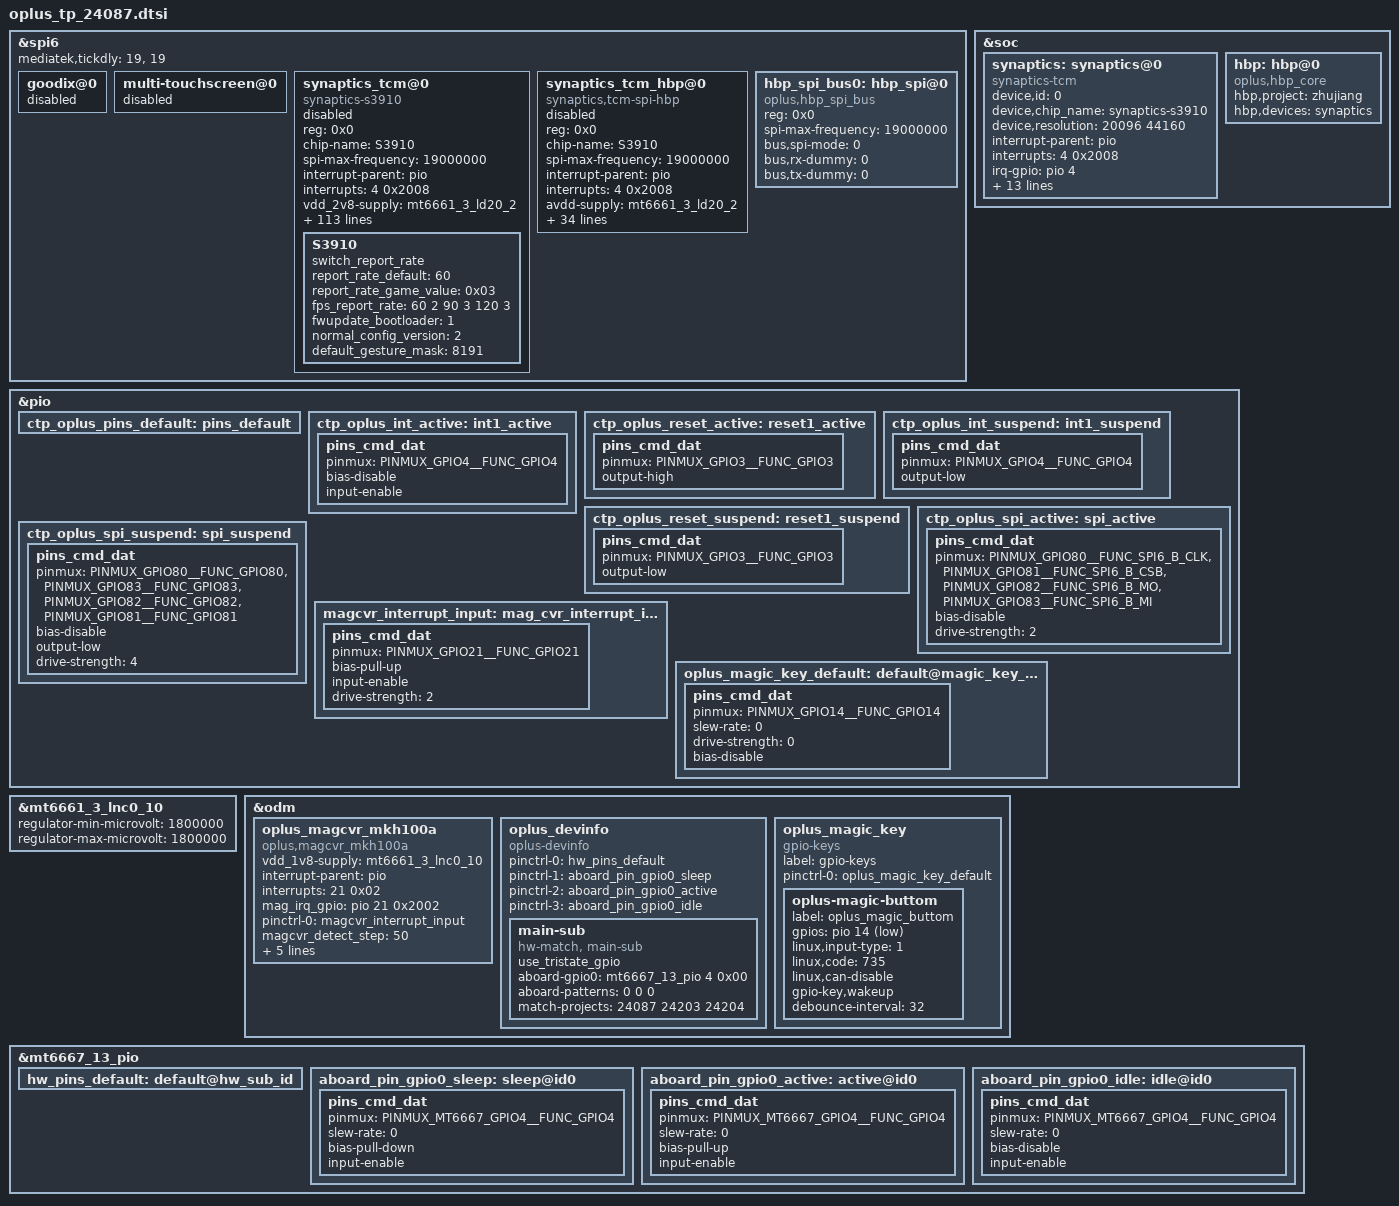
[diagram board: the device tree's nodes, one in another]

#include <dt-bindings/pinctrl/mt6667-pinfunc.h>

/* TOUCH start */

&spi6 {
	status = "okay";
	#address-cells = <1>;
	#size-cells = <0>;
	mediatek,tickdly = <19>, <19>;

	goodix@0{
		status = "disabled";
	};

	multi-touchscreen@0{
		status = "disabled";
	};

	synaptics_tcm@0{
		compatible = "synaptics-s3910";
		reg = <0x0>;
		chip-name = "S3910";
		status = "disabled";
		spi-max-frequency = <19000000>;
		/* Interrupt && Irq-gpio */
		interrupt-parent = <&pio>;
		interrupts = <4 0x2008>;

		/* Power Config */
		/* enable2v8_gpio  = <&pio 164 0x1>; */
		vdd_2v8-supply = <&mt6661_3_ld20_2>;
		vdd_2v8_volt = <3000000>;
		vcc_1v8-supply  = <&mt6661_5_ln60_7>;
		vcc_1v8_volt = <1800000>;

		/* Other HW Resource */

		irq-gpio = <&pio 4 0x2008>;
		reset-gpio = <&pio 3 0x1>;
		//cs-gpio = <&pio 110 0x00>;

		pinctrl-names = "default",  "oplus_int_active",
		"oplus_reset_active", "oplus_int_suspend",
		"oplus_reset_suspend", "oplus_spi_active",
		"oplus_spi_suspend";
		pinctrl-0 = <&ctp_oplus_pins_default>;
		pinctrl-1 = <&ctp_oplus_int_active>;
		pinctrl-2 = <&ctp_oplus_reset_active>;
		pinctrl-3 = <&ctp_oplus_int_suspend>;
		pinctrl-4 = <&ctp_oplus_reset_suspend>;
		pinctrl-5 = <&ctp_oplus_spi_active>;
		pinctrl-6 = <&ctp_oplus_spi_suspend>;

		touchpanel,max-num-support = <10>;
		touchpanel,tx-rx-num = <18 40>;
		touchpanel,panel-coords = <12560 27600>;
		touchpanel,display-coords = <1256 2760>;
		touchpanel,touchmajor-limit = <128 216>;
		touchpanel,elimination-range = <20 200 200>;
		touchpanel,int-mode = <1>; /*0: interrupt and disable, 1:interrupt and not disable*/
		touchpanel,smooth-level = <0 1 2 4 7 9>;
		touchpanel,smooth-level-charging = <0 2 4 7 8 9>;
		touchpanel,sensitive-level = <0 70 55 40 25 10>;
		touchpanel,single-optimized-time = <8>;
		touchpanel,high-frame-rate-time = <60>;

		vid_len = <2>;
		panel_type = <7>; /*type:3 BOE, 7 TM*/
		platform_support_project = <24087 24203 24204>;
		platform_support_project_dir = <24087 24087 24087>;
		platform_support_project_commandline = "panel_ac287_p_7_a0020_dsi_cmd";

		prevention,curved_screen_V2;
		prevention,grip_disable_level = <6>;
		prevention,updelay_time_ms = <30>;
		prevention,makeup_cnt_weight = <4 1 2 2 2>;
		prevention,large_corner_range = <1380 3400>;
		prevention,large_corner_judge_condition = <500 300 1000 7 7>;
		prevention,trx_reject_condition = <8 7 7>;
		prevention,trx_strict_reject_condition = <8 6 6>;
		prevention,large_judge_time_ms = <500 50 30>;
		prevention,large_exit_condition = <8 8 2>;
		prevention,single_channel_width = <320 320>;
		prevention,normal_tap_condition = <10 350>;
		prevention,long_edge_condition = <179 90 120 80>;
		prevention,long_strict_edge_condition = <160 60>;
		prevention,long_fingerhold_condition = <70 6 4 4>;
		prevention,short_edge_condition = <179 90 120 80>;
		prevention,short_strict_edge_condition = <160 60>;
		prevention,large_strict_exit_condition = <6 6>;
		prevention,top_corner_config = <250 750 1000>;
		prevention,edge_swipe_config = <340 1130>;

		prevention,curved_screen_V4;
		prevention,long_eliminate_point_type = <2 12400 9240 240 27720 300 1>;
		prevention,long_fingerhold_condition2 = <700 2000 0 0>;
		prevention,top_corner_config2 =<3 80 600 1500 0>;
		prevention,hor_long_top_corner_config =<300 2000 0 0>;
		prevention,top_middle_config =<12400 1000 1000 0>;
		prevention,corner_eliminate_point_type =<0 1380 2270 1>;
		prevention,finger_hold_differ_size = <1 0 400 300>;
		prevention,finger_hold_max_rx_exit_distance = <5 350 2300>;
		prevention,max_rx_exit_distance = <1 5 150 350 2000>;
		prevention,dynamic_finger_hold_exit_distance = <1 350 2300 450>;
		prevention,edge_sliding_matched_support = <1 150 3 0>;

		//grip v4.2 reclining mode
		prevention,reclining_mode_support = <1>;
		prevention,long_eliminate_point_type_recli = <2 12400 9240 240 27720 500 1>;
		prevention,finger_hold_differ_size_recli = <1 0 400 400>;
		prevention,finger_hold_max_rx_exit_distance_recli = <5 350 2300>;
		prevention,max_rx_exit_distance_recli = <1 5 100 350 2300>;
		prevention,dynamic_finger_hold_exit_distance_recli = <1 350 2300 450>;
		prevention,edge_sliding_matched_support_recli = <1 150 3 0>;
		prevention,long_edge_condition_recli = <179 90 120 80>;

		/* SW Support Feature Control */
		black_gesture_support;
		sportify_aod_gesture_support;
		pressure_report_support;
		charger_pump_support;
		game_switch_support;
		glove_mode_support;
		smart_gesture_support;
		fw_update_app_support;
		fingerprint_underscreen_support;
		freq_hop_simulate_support;
		report_flow_unlock_support;
		screenoff_fingerprint_info_support;
		irq_need_dev_resume_ok;
		enable_point_auto_change;
		kernel_grip_support;
		//grip_no_driver_support;
		health_monitor_support;
		black_gesture_indep_support;
		snr_read_support;
		palm_to_sleep_support;
		exception_upload_support;
		tp_data_record_support;
		fingerprint_not_report_in_suspend;
		/*
		 *Virtual Key Config:
		 *1:touchpanel,button-type: <virtualkey_type  supportted_button-map>
		 *virtualkey_type:
		 *Type 1: using board_properties
		 *Type 2: using same IC (button zone&& touch zone are seprate)
		 *Type 3: using diffrent IC (button zone&& touch zone are seprate)
		 *Type 4: No need of virtual key process
		 *supportted_button-map:select|menu|home|back
		 *
		 *2:touchpanel,button-map
		 *type (X1,Y1)(X2,Y2)(X3,Y3)(Width_X,Hight_Y)--Only when button-type is 0
		 */
		touchpanel,button-type = <4>;
		touchpanel.button-TRx = <0 0>;

		S3910 {
			switch_report_rate;
			report_rate_default = <60>;
			report_rate_game_value = <0x03>;
			fps_report_rate = <60 2 90 3 120 3>;//1:360Hz 2:125Hz 3:240Hz
			fwupdate_bootloader = <1>;
			normal_config_version = <2>;
			default_gesture_mask = <8191>;
		};
	};
	synaptics_tcm_hbp@0{
		compatible = "synaptics,tcm-spi-hbp";
		reg = <0x0>;
		chip-name = "S3910";
		status = "disabled";
		spi-max-frequency = <19000000>;

		/* Interrupt && Irq-gpio */
		interrupt-parent = <&pio>;
		interrupts = <4 0x2008>;

		/* Power Config */
		/* enable2v8_gpio  = <&pio 164 0x1>; */
		/* synaptics,avdd-gpio = <&pio 186 0x1>; */
		avdd-supply = <&mt6661_3_ld20_2>;
		synaptics,avdd-name = "avdd";
		synaptics,vdd_2v8_volt = <3000000>;
		vdd-supply  = <&mt6661_5_ln60_7>;
		synaptics,vdd-name = "vdd";

		/* Other HW Resource */

		synaptics,irq-gpio = <&pio 4 0x2008>;
		synaptics,reset-gpio = <&pio 3 0x1>;
		//cs-gpio = <&pio 110 0x00>;

		pinctrl-names = "default", "ts_spi_active", "ts_spi_suspend";
		pinctrl-0 = <&ctp_oplus_pins_default>;
		pinctrl-1 = <&ctp_oplus_int_active &ctp_oplus_reset_active &ctp_oplus_spi_active>;
		pinctrl-2 = <&ctp_oplus_int_suspend &ctp_oplus_reset_suspend &ctp_oplus_spi_suspend>;

		touchpanel,max-num-support = <10>;
		touchpanel,tx-rx-num = <18 40>;
		touchpanel,panel-coords = <20096 44160>;
		touchpanel,display-coords = <1256 2760>;
		vid_len = <2>;
		panel_type = <7>; /*type:3 BOE, 7 TM*/
		platform_support_project = <24087 24203 24204>;
		platform_support_project_dir = <24087 24087 24087>;
		platform_support_project_commandline = "panel_ac287_p_7_a0020_dsi_cmd";

		synaptics,power-on-state = <1>;
		synaptics,power-delay-ms = <200>;
		synaptics,irq-on-state = <0>;
		synaptics,reset-on-state = <0>;
		synaptics,reset-active-ms = <10>;
		synaptics,reset-delay-ms = <80>;
		synaptics,spi-mode = <0>;
		synaptics,spi-byte-delay-us = <0>;
		synaptics,spi-block-delay-us = <0>;

		tp_data_record_support;
		stats_upload_support;
	};

	hbp_spi_bus0:hbp_spi@0 {
		compatible = "oplus,hbp_spi_bus";
		reg = <0x0>;
		status = "okay";

		spi-max-frequency = <19000000>;
		bus,spi-mode = <0>;
		bus,rx-dummy = <0>;
		bus,tx-dummy = <0>;
	};
};

&soc {
	synaptics:synaptics@0 {
		compatible = "synaptics-tcm";
		status = "okay";

		device,id = <0>;
		device,chip_name = "synaptics-s3910";
		device,resolution = <20096 44160>;

		/*interrupt config*/
		interrupt-parent = <&pio>;
		interrupts = <4 0x2008>;
		irq-gpio = <&pio 4 0x2008>;

		pinctrl-names = "default",
				"ts_reset_active",
				"ts_reset_idle",
				"ts_resume",
				"ts_suspend";
		pinctrl-0 = <&ctp_oplus_int_active &ctp_oplus_reset_active &ctp_oplus_spi_active>;
		pinctrl-1 = <&ctp_oplus_reset_active>;
		pinctrl-2 = <&ctp_oplus_reset_suspend>;
		pinctrl-3 = <&ctp_oplus_spi_active>;
		pinctrl-4 = <&ctp_oplus_spi_suspend>;

		/*cs active state, not used now*/
		spi,cs_active = <0>;

		/*power config*/
		power,avdd-supply = <&mt6661_3_ld20_2>;
		power,avdd_volt = <3000000 3000000>;

		power,vddi-supply = <&mt6661_5_ln60_7>;
		power,vddi_volt = <1800000 1800000>;

		/*bus config*/
		device,attached_bus = <&hbp_spi_bus0>;

		create_with_power_on_support;
	};

	hbp:hbp@0 {
		compatible = "oplus,hbp_core";
		hbp,project = "zhujiang";
		hbp,devices = <&synaptics>;
	};
};

/*add for  TP*/
&pio {
	ctp_oplus_pins_default: pins_default {
	};
	ctp_oplus_int_active: int1_active {
		pins_cmd_dat {
			pinmux = <PINMUX_GPIO4__FUNC_GPIO4>;
			bias-disable;
			input-enable;
		};
	};
	ctp_oplus_reset_active: reset1_active {
		pins_cmd_dat {
			pinmux = <PINMUX_GPIO3__FUNC_GPIO3>;
			output-high;
		};
	};
	ctp_oplus_int_suspend: int1_suspend {
		pins_cmd_dat {
			pinmux = <PINMUX_GPIO4__FUNC_GPIO4>;
			output-low;
		};
	};
	ctp_oplus_reset_suspend: reset1_suspend {
		pins_cmd_dat {
			pinmux = <PINMUX_GPIO3__FUNC_GPIO3>;
			output-low;
		};
	};
	ctp_oplus_spi_active: spi_active {
		pins_cmd_dat {
			pinmux = <PINMUX_GPIO80__FUNC_SPI6_B_CLK>,
				<PINMUX_GPIO81__FUNC_SPI6_B_CSB>,
				<PINMUX_GPIO82__FUNC_SPI6_B_MO>,
				<PINMUX_GPIO83__FUNC_SPI6_B_MI>;
			bias-disable;
			drive-strength = <2>;
		};
	};
	ctp_oplus_spi_suspend: spi_suspend {
		pins_cmd_dat {
			pinmux = < PINMUX_GPIO80__FUNC_GPIO80>,
				< PINMUX_GPIO83__FUNC_GPIO83>,
				<PINMUX_GPIO82__FUNC_GPIO82>,
				<PINMUX_GPIO81__FUNC_GPIO81>;
			bias-disable;
			output-low;
			drive-strength = <4>;
		};
	};
};

/* key start */
&mt6661_3_lnc0_10 {
	regulator-min-microvolt = <1800000>;
	regulator-max-microvolt = <1800000>;
};

&odm {
	oplus_magcvr_mkh100a:oplus_magcvr_mkh100a {
		compatible = "oplus,magcvr_mkh100a";
		vdd_1v8-supply = <&mt6661_3_lnc0_10>;
		// vcc_3v0-supply = <&mt6368_vio28>;
		// vdd_3v0_volt = <3100000>;
		interrupt-parent = <&pio>;
		interrupts = <21 0x02>;
		mag_irq_gpio = <&pio 21 0x2002>;
		pinctrl-names = "default";
		pinctrl-0 = <&magcvr_interrupt_input>;
		// para config
		magcvr_detect_step = <50>;
		magcvr_farmax_th = <50>;
		magcvr_far_threshold = <150>;
		magcvr_far_noise_threshold = <125>;
		magcvr_irq_type = <4>;
		no_need_calibration;
	};

	oplus_devinfo:oplus_devinfo {
			compatible = "oplus-devinfo";
			pinctrl-names = "default", "aboard_gpio0_sleep", "aboard_gpio0_active", "aboard_gpio0_idle";
			pinctrl-0 = <&hw_pins_default>;
			pinctrl-1 = <&aboard_pin_gpio0_sleep>;
			pinctrl-2 = <&aboard_pin_gpio0_active>;
			pinctrl-3 = <&aboard_pin_gpio0_idle>;
			main-sub {
					use_tristate_gpio;
					compatible = "hw-match, main-sub";
					aboard-gpio0 = <&mt6667_13_pio 4 0x00>;
					aboard-patterns = <0 0 0>;        //0[high-resistance] 1[pull-down] 2[pull-up]
					//main board
					match-projects = <24087 24203 24204>;
			};
	};

	oplus_magic_key:oplus_magic_key {
		compatible = "gpio-keys";
		label = "gpio-keys";
		status = "okay";
		pinctrl-0 = <&oplus_magic_key_default>;
		pinctrl-names = "default";
		oplus-magic-buttom {
			label = "oplus_magic_buttom";
			gpios = <&pio 14 0x01>;
			linux,input-type = <1>; /* EV_KEY */
			linux,code = <735>; /* means: BTN_TRIGGER_HAPPY32 */
			linux,can-disable;
			gpio-key,wakeup;
			debounce-interval = <32>; /* standard debounce time 32ms */
		};
	};
};

&pio {
	magcvr_interrupt_input: mag_cvr_interrupt_input {
		pins_cmd_dat {
			pinmux = <PINMUX_GPIO21__FUNC_GPIO21>;
			bias-pull-up;
			input-enable;
			drive-strength = <2>;
		};
	};

	oplus_magic_key_default:default@magic_key_id {
		pins_cmd_dat {
			pinmux = <PINMUX_GPIO14__FUNC_GPIO14>;
			slew-rate = <0>;
			drive-strength = <0>;
			bias-disable;
		};
	};
};

&mt6667_13_pio {
	hw_pins_default:default@hw_sub_id {
	};

	aboard_pin_gpio0_sleep:sleep@id0 {
		pins_cmd_dat {
			pinmux = <PINMUX_MT6667_GPIO4__FUNC_GPIO4>;
			slew-rate = <0>;
			bias-pull-down;
			input-enable;
		};
	};

	aboard_pin_gpio0_active:active@id0 {
		pins_cmd_dat {
			pinmux = <PINMUX_MT6667_GPIO4__FUNC_GPIO4>;
			slew-rate = <0>;
			bias-pull-up;
			input-enable;
		};
	};

	aboard_pin_gpio0_idle:idle@id0 {
		pins_cmd_dat {
			pinmux = <PINMUX_MT6667_GPIO4__FUNC_GPIO4>;
			slew-rate = <0>;
			bias-disable;
			input-enable;
		};
	};
};
